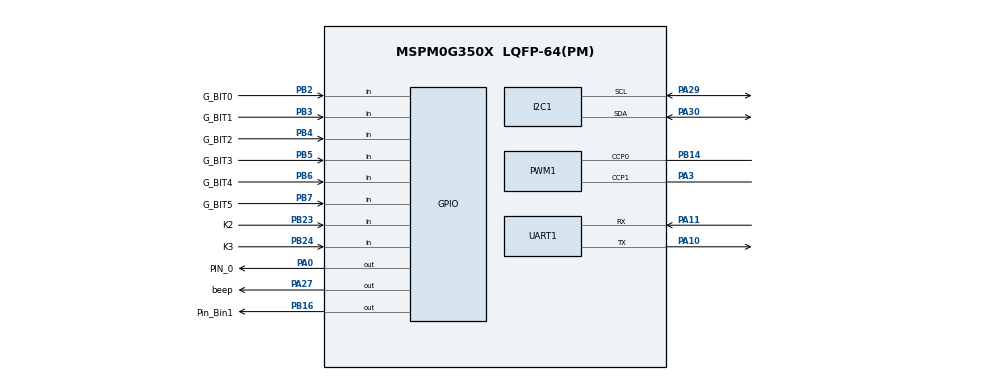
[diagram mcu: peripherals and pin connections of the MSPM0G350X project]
/**
 * @cliArgs --device "MSPM0G350X" --package "LQFP-64(PM)" --part "Default" --product "mspm0_sdk@2.01.00.03"
 * @versions {"tool":"1.19.0+3426"}
 */

/**
 * Import the modules used in this configuration.
 */
const GPIO          = scripting.addModule("/ti/driverlib/GPIO", {}, false);
const GPIO1         = GPIO.addInstance();
const GPIO2         = GPIO.addInstance();
const GPIO3         = GPIO.addInstance();
const GPIO4         = GPIO.addInstance();
const GPIO5         = GPIO.addInstance();
const GPIO6         = GPIO.addInstance();
const GPIO7         = GPIO.addInstance();
const GPIO8         = GPIO.addInstance();
const GPIO9         = GPIO.addInstance();
const GPIO10        = GPIO.addInstance();
const GPIO11        = GPIO.addInstance();
const I2C           = scripting.addModule("/ti/driverlib/I2C", {}, false);
const I2C1          = I2C.addInstance();
const PWM           = scripting.addModule("/ti/driverlib/PWM", {}, false);
const PWM1          = PWM.addInstance();
const SYSCTL        = scripting.addModule("/ti/driverlib/SYSCTL");
const SYSTICK       = scripting.addModule("/ti/driverlib/SYSTICK");
const TIMER         = scripting.addModule("/ti/driverlib/TIMER", {}, false);
const TIMER1        = TIMER.addInstance();
const TIMER2        = TIMER.addInstance();
const UART          = scripting.addModule("/ti/driverlib/UART", {}, false);
const UART1         = UART.addInstance();
const ProjectConfig = scripting.addModule("/ti/project_config/ProjectConfig");

/**
 * Write custom configuration values to the imported modules.
 */
const divider7       = system.clockTree["PLL_PDIV"];
divider7.divideValue = 2;

const divider9       = system.clockTree["UDIV"];
divider9.divideValue = 2;

const gate7  = system.clockTree["MFCLKGATE"];
gate7.enable = true;

const multiplier2         = system.clockTree["PLL_QDIV"];
multiplier2.multiplyValue = 10;

const mux8       = system.clockTree["HSCLKMUX"];
mux8.inputSelect = "HSCLKMUX_SYSPLL0";

GPIO1.$name                              = "KEY";
GPIO1.port                               = "PORTB";
GPIO1.associatedPins.create(3);
GPIO1.associatedPins[0].direction        = "INPUT";
GPIO1.associatedPins[0].polarity         = "RISE";
GPIO1.associatedPins[0].assignedPin      = "21";
GPIO1.associatedPins[0].$name            = "K1";
GPIO1.associatedPins[0].internalResistor = "PULL_UP";
GPIO1.associatedPins[1].$name            = "K2";
GPIO1.associatedPins[1].direction        = "INPUT";
GPIO1.associatedPins[1].internalResistor = "PULL_UP";
GPIO1.associatedPins[1].pin.$assign      = "PB23";
GPIO1.associatedPins[2].$name            = "K3";
GPIO1.associatedPins[2].direction        = "INPUT";
GPIO1.associatedPins[2].internalResistor = "PULL_UP";
GPIO1.associatedPins[2].pin.$assign      = "PB24";

const Board = scripting.addModule("/ti/driverlib/Board", {}, false);

GPIO2.$name                               = "ENCODERA";
GPIO2.port                                = "PORTA";
GPIO2.associatedPins.create(2);
GPIO2.associatedPins[0].direction         = "INPUT";
GPIO2.associatedPins[0].interruptPriority = "1";
GPIO2.associatedPins[0].interruptEn       = true;
GPIO2.associatedPins[0].polarity          = "RISE_FALL";
GPIO2.associatedPins[0].$name             = "E1A";
GPIO2.associatedPins[0].assignedPin       = "15";
GPIO2.associatedPins[1].direction         = "INPUT";
GPIO2.associatedPins[1].interruptEn       = true;
GPIO2.associatedPins[1].interruptPriority = "1";
GPIO2.associatedPins[1].polarity          = "RISE_FALL";
GPIO2.associatedPins[1].$name             = "E1B";
GPIO2.associatedPins[1].assignedPin       = "16";

GPIO3.$name                         = "RGB_Red";
GPIO3.port                          = "PORTB";
GPIO3.associatedPins[0].$name       = "PIN_26";
GPIO3.associatedPins[0].assignedPin = "26";

GPIO4.$name                               = "ENCODERB";
GPIO4.port                                = "PORTA";
GPIO4.associatedPins.create(2);
GPIO4.associatedPins[0].direction         = "INPUT";
GPIO4.associatedPins[0].interruptPriority = "1";
GPIO4.associatedPins[0].$name             = "E2A";
GPIO4.associatedPins[0].assignedPin       = "17";
GPIO4.associatedPins[0].interruptEn       = true;
GPIO4.associatedPins[0].polarity          = "RISE";
GPIO4.associatedPins[1].direction         = "INPUT";
GPIO4.associatedPins[1].interruptPriority = "1";
GPIO4.associatedPins[1].$name             = "E2B";
GPIO4.associatedPins[1].assignedPin       = "22";
GPIO4.associatedPins[1].interruptEn       = true;
GPIO4.associatedPins[1].polarity          = "RISE";

GPIO5.$name                   = "AIN1";
GPIO5.port                    = "PORTA";
GPIO5.associatedPins[0].$name = "PIN_12";

GPIO6.$name                         = "AIN2";
GPIO6.port                          = "PORTA";
GPIO6.associatedPins[0].$name       = "PIN_13";
GPIO6.associatedPins[0].assignedPin = "13";

GPIO7.$name                         = "BIN1";
GPIO7.port                          = "PORTB";
GPIO7.associatedPins[0].$name       = "Pin_Bin1";
GPIO7.associatedPins[0].pin.$assign = "PB16";

GPIO8.$name                         = "BIN2";
GPIO8.port                          = "PORTB";
GPIO8.associatedPins[0].$name       = "Pin_Bin2";
GPIO8.associatedPins[0].assignedPin = "0";

GPIO9.$name                              = "GPIO_GRAY";
GPIO9.port                               = "PORTB";
GPIO9.associatedPins.create(6);
GPIO9.associatedPins[0].$name            = "G_BIT0";
GPIO9.associatedPins[0].direction        = "INPUT";
GPIO9.associatedPins[0].internalResistor = "PULL_UP";
GPIO9.associatedPins[0].pin.$assign      = "PB2";
GPIO9.associatedPins[1].$name            = "G_BIT1";
GPIO9.associatedPins[1].direction        = "INPUT";
GPIO9.associatedPins[1].internalResistor = "PULL_UP";
GPIO9.associatedPins[1].pin.$assign      = "PB3";
GPIO9.associatedPins[2].$name            = "G_BIT2";
GPIO9.associatedPins[2].direction        = "INPUT";
GPIO9.associatedPins[2].internalResistor = "PULL_UP";
GPIO9.associatedPins[2].pin.$assign      = "PB4";
GPIO9.associatedPins[3].$name            = "G_BIT3";
GPIO9.associatedPins[3].direction        = "INPUT";
GPIO9.associatedPins[3].internalResistor = "PULL_UP";
GPIO9.associatedPins[3].pin.$assign      = "PB5";
GPIO9.associatedPins[4].$name            = "G_BIT4";
GPIO9.associatedPins[4].direction        = "INPUT";
GPIO9.associatedPins[4].internalResistor = "PULL_UP";
GPIO9.associatedPins[4].pin.$assign      = "PB6";
GPIO9.associatedPins[5].$name            = "G_BIT5";
GPIO9.associatedPins[5].direction        = "INPUT";
GPIO9.associatedPins[5].internalResistor = "PULL_UP";
GPIO9.associatedPins[5].pin.$assign      = "PB7";

GPIO10.$name                         = "PORTA";
GPIO10.port                          = "PORTA";
GPIO10.associatedPins[0].$name       = "beep";
GPIO10.associatedPins[0].pin.$assign = "PA27";

GPIO11.$name                          = "LED1";
GPIO11.associatedPins[0].$name        = "PIN_0";
GPIO11.associatedPins[0].assignedPort = "PORTA";
GPIO11.associatedPins[0].pin.$assign  = "PA0";

I2C1.$name                             = "I2C_MPU6050";
I2C1.basicEnableController             = true;
I2C1.intController                     = ["ARBITRATION_LOST","NACK","RXFIFO_TRIGGER","RX_DONE","TX_DONE"];
I2C1.interruptPriority                 = "0";
I2C1.peripheral.$assign                = "I2C1";
I2C1.peripheral.sdaPin.$assign         = "PA30";
I2C1.peripheral.sclPin.$assign         = "PA29";
I2C1.sdaPinConfig.hideOutputInversion  = scripting.forceWrite(false);
I2C1.sdaPinConfig.onlyInternalResistor = scripting.forceWrite(false);
I2C1.sdaPinConfig.passedPeripheralType = scripting.forceWrite("Digital");
I2C1.sdaPinConfig.$name                = "ti_driverlib_gpio_GPIOPinGeneric6";
I2C1.sclPinConfig.hideOutputInversion  = scripting.forceWrite(false);
I2C1.sclPinConfig.onlyInternalResistor = scripting.forceWrite(false);
I2C1.sclPinConfig.passedPeripheralType = scripting.forceWrite("Digital");
I2C1.sclPinConfig.$name                = "ti_driverlib_gpio_GPIOPinGeneric7";

PWM1.$name                      = "PWM_0";
PWM1.timerCount                 = 3200;
PWM1.pwmMode                    = "EDGE_ALIGN_UP";
PWM1.timerStartTimer            = true;
PWM1.clockDivider               = 3;
PWM1.peripheral.ccp0Pin.$assign = "PB14";
PWM1.peripheral.ccp1Pin.$assign = "PA3";
PWM1.PWM_CHANNEL_0.$name        = "ti_driverlib_pwm_PWMTimerCC0";
PWM1.PWM_CHANNEL_1.$name        = "ti_driverlib_pwm_PWMTimerCC1";
PWM1.ccp0PinConfig.$name        = "ti_driverlib_gpio_GPIOPinGeneric2";
PWM1.ccp1PinConfig.$name        = "ti_driverlib_gpio_GPIOPinGeneric3";

SYSCTL.forceDefaultClkConfig = true;
SYSCTL.clockTreeEn           = true;

SYSTICK.periodEnable      = true;
SYSTICK.systickEnable     = true;
SYSTICK.interruptPriority = "0";
SYSTICK.period            = 80;

TIMER1.$name             = "TIMER_0";
TIMER1.timerClkPrescale  = 200;
TIMER1.timerPeriod       = "5 ms";
TIMER1.timerStartTimer   = true;
TIMER1.timerMode         = "PERIODIC";
TIMER1.interrupts        = ["ZERO"];
TIMER1.timerClkDiv       = 8;
TIMER1.interruptPriority = "1";

TIMER2.$name             = "TIMER_GYRO";
TIMER2.timerClkDiv       = 4;
TIMER2.timerClkPrescale  = 10;
TIMER2.timerStartTimer   = true;
TIMER2.interrupts        = ["ZERO"];
TIMER2.timerMode         = "PERIODIC";
TIMER2.interruptPriority = "3";
TIMER2.timerPeriod       = "10 ms";

UART1.$name                    = "UART_0";
UART1.enabledInterrupts        = ["RX"];
UART1.targetBaudRate           = 115200;
UART1.interruptPriority        = "1";
UART1.enableDMARX              = false;
UART1.peripheral.$assign       = "UART0";
UART1.peripheral.rxPin.$assign = "PA11";
UART1.peripheral.txPin.$assign = "PA10";
UART1.txPinConfig.$name        = "ti_driverlib_gpio_GPIOPinGeneric0";
UART1.rxPinConfig.$name        = "ti_driverlib_gpio_GPIOPinGeneric1";

ProjectConfig.genLibCMSIS = true;

/**
 * Pinmux solution for unlocked pins/peripherals. This ensures that minor changes to the automatic solver in a future
 * version of the tool will not impact the pinmux you originally saw.  These lines can be completely deleted in order to
 * re-solve from scratch.
 */
GPIO1.associatedPins[0].pin.$suggestSolution = "PB21";
Board.peripheral.$suggestSolution            = "DEBUGSS";
Board.peripheral.swclkPin.$suggestSolution   = "PA20";
Board.peripheral.swdioPin.$suggestSolution   = "PA19";
GPIO2.associatedPins[0].pin.$suggestSolution = "PA15";
GPIO2.associatedPins[1].pin.$suggestSolution = "PA16";
GPIO3.associatedPins[0].pin.$suggestSolution = "PB26";
GPIO4.associatedPins[0].pin.$suggestSolution = "PA17";
GPIO4.associatedPins[1].pin.$suggestSolution = "PA22";
GPIO5.associatedPins[0].pin.$suggestSolution = "PA12";
GPIO6.associatedPins[0].pin.$suggestSolution = "PA13";
GPIO8.associatedPins[0].pin.$suggestSolution = "PB0";
PWM1.peripheral.$suggestSolution             = "TIMA0";
TIMER1.peripheral.$suggestSolution           = "TIMG0";
TIMER2.peripheral.$suggestSolution           = "TIMA1";
